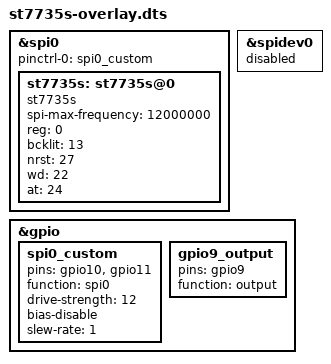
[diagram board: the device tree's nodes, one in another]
/dts-v1/;
/plugin/;

/ {
	fragment@0 {
		target = <&spi0>;
		__overlay__ {
			status = "okay";
			#address-cells = <1>;
			#size-cells = <0>;
			pinctrl-names = "default";
			pinctrl-0 = <&spi0_custom>;
			st7735s: st7735s@0 {
				compatible = "st7735s";
				spi-max-frequency = <12000000>;
				status = "okay";
				reg = <0>;
				bcklit = <13>;
				nrst = <27>;
				wd = <22>;
				at = <24>;
			};
		};
	};

	fragment@1 {
		target = <&spidev0>;
		__overlay__ {
			status = "disabled";
		};
	};

	fragment@2 {
		target = <&gpio>;
		__overlay__ {
			spi0_custom: spi0_custom {
				pins = "gpio10", "gpio11";
				function = "spi0";
				drive-strength = <12>;
				bias-disable;
				slew-rate = <1>;
			};
			gpio9_output: gpio9_output {
				pins = "gpio9";
				function = "output";
			};
		};
	};
};
